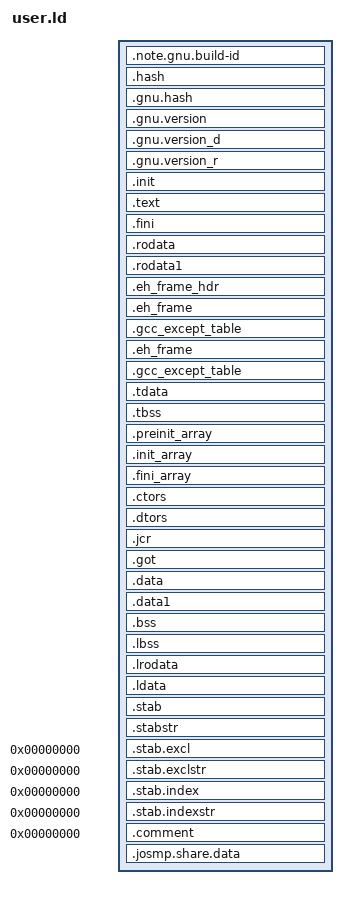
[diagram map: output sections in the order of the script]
/* Script for -z combreloc: combine and sort reloc sections */
OUTPUT_FORMAT("elf64-x86-64", "elf64-x86-64",
	      "elf64-x86-64")
OUTPUT_ARCH(i386:x86-64)
ENTRY(_start)

PHDRS
{
  text PT_LOAD FILEHDR PHDRS ;
  data PT_LOAD ;
  stab PT_LOAD ;
  josmp PT_LOAD ;
}

SECTIONS
{
  /* Read-only sections, merged into text segment: */
  PROVIDE (__executable_start = 0x400000); . = 0x400000 + SIZEOF_HEADERS;
  .note.gnu.build-id : { *(.note.gnu.build-id) }
  .hash           : { *(.hash) }
  .gnu.hash       : { *(.gnu.hash) }
  .gnu.version    : { *(.gnu.version) }
  .gnu.version_d  : { *(.gnu.version_d) }
  .gnu.version_r  : { *(.gnu.version_r) }
  .init           :
  {
    KEEP (*(.init))
  } : text =0x90909090
  .text           :
  {
    *(.text .stub .text.* .gnu.linkonce.t.*)
    KEEP (*(.text.*personality*))
    /* .gnu.warning sections are handled specially by elf32.em.  */
    *(.gnu.warning)
  } =0x90909090
  .fini           :
  {
    KEEP (*(.fini))
  } =0x90909090
  PROVIDE (__etext = .);
  PROVIDE (_etext = .);
  PROVIDE (etext = .);
  .rodata         : { *(.rodata .rodata.* .gnu.linkonce.r.*) }
  .rodata1        : { *(.rodata1) }
  .eh_frame_hdr : { *(.eh_frame_hdr) }
  .eh_frame       : ONLY_IF_RO { KEEP (*(.eh_frame)) }
  .gcc_except_table   : ONLY_IF_RO { *(.gcc_except_table .gcc_except_table.*) }
  /* Adjust the address for the data segment.  We want to adjust up to
     the same address within the page on the next page up.  */
  . = ALIGN (CONSTANT (MAXPAGESIZE)) - ((CONSTANT (MAXPAGESIZE) - .) & (CONSTANT (MAXPAGESIZE) - 1)); . = DATA_SEGMENT_ALIGN (CONSTANT (MAXPAGESIZE), CONSTANT (COMMONPAGESIZE));
  /* Exception handling  */
  .eh_frame       : ONLY_IF_RW { KEEP (*(.eh_frame)) }
  .gcc_except_table   : ONLY_IF_RW { *(.gcc_except_table .gcc_except_table.*) }
  /* Thread Local Storage sections  */
  .tdata	  : { *(.tdata .tdata.* .gnu.linkonce.td.*) }
  .tbss		  : { *(.tbss .tbss.* .gnu.linkonce.tb.*) *(.tcommon) }
  .preinit_array     :
  {
    PROVIDE_HIDDEN (__preinit_array_start = .);
    KEEP (*(.preinit_array))
    PROVIDE_HIDDEN (__preinit_array_end = .);
  }
  .init_array     :
  {
     PROVIDE_HIDDEN (__init_array_start = .);
     KEEP (*(SORT(.init_array.*)))
     KEEP (*(.init_array))
     PROVIDE_HIDDEN (__init_array_end = .);
  }
  .fini_array     :
  {
    PROVIDE_HIDDEN (__fini_array_start = .);
    KEEP (*(.fini_array))
    KEEP (*(SORT(.fini_array.*)))
    PROVIDE_HIDDEN (__fini_array_end = .);
  }
  .ctors          :
  {
    /* gcc uses crtbegin.o to find the start of
       the constructors, so we make sure it is
       first.  Because this is a wildcard, it
       doesn't matter if the user does not
       actually link against crtbegin.o; the
       linker won't look for a file to match a
       wildcard.  The wildcard also means that it
       doesn't matter which directory crtbegin.o
       is in.  */
    KEEP (*crtbegin.o(.ctors))
    KEEP (*crtbegin?.o(.ctors))
    /* We don't want to include the .ctor section from
       the crtend.o file until after the sorted ctors.
       The .ctor section from the crtend file contains the
       end of ctors marker and it must be last */
    KEEP (*(EXCLUDE_FILE (*crtend.o *crtend?.o ) .ctors))
    KEEP (*(SORT(.ctors.*)))
    KEEP (*(.ctors))
  } : data
  .dtors          :
  {
    KEEP (*crtbegin.o(.dtors))
    KEEP (*crtbegin?.o(.dtors))
    KEEP (*(EXCLUDE_FILE (*crtend.o *crtend?.o ) .dtors))
    KEEP (*(SORT(.dtors.*)))
    KEEP (*(.dtors))
  }
  .jcr            : { KEEP (*(.jcr)) }
  .got            : { *(.got) }
  . = DATA_SEGMENT_RELRO_END (24, .);
  .data           :
  {
    *(.data .data.* .gnu.linkonce.d.*)
    KEEP (*(.gnu.linkonce.d.*personality*))
    SORT(CONSTRUCTORS)
  }
  .data1          : { *(.data1) }
  _edata = .; PROVIDE (edata = .);
  __bss_start = .;
  .bss            :
  {
   *(.dynbss)
   *(.bss .bss.* .gnu.linkonce.b.*)
   *(COMMON)
   /* Align here to ensure that the .bss section occupies space up to
      _end.  Align after .bss to ensure correct alignment even if the
      .bss section disappears because there are no input sections.
      FIXME: Why do we need it? When there is no .bss section, we don't
      pad the .data section.  */
   . = ALIGN(. != 0 ? 64 / 8 : 1);
  }
  .lbss   :
  {
    *(.dynlbss)
    *(.lbss .lbss.* .gnu.linkonce.lb.*)
    *(LARGE_COMMON)
  }
  . = ALIGN(64 / 8);
  .lrodata   ALIGN(CONSTANT (MAXPAGESIZE)) + (. & (CONSTANT (MAXPAGESIZE) - 1)) :
  {
    *(.lrodata .lrodata.* .gnu.linkonce.lr.*)
  }
  .ldata   ALIGN(CONSTANT (MAXPAGESIZE)) + (. & (CONSTANT (MAXPAGESIZE) - 1)) :
  {
    *(.ldata .ldata.* .gnu.linkonce.l.*)
    . = ALIGN(. != 0 ? 64 / 8 : 1);
  }
  . = ALIGN(64 / 8);
  _end = .; PROVIDE (end = .);
  . = DATA_SEGMENT_END (.);
  /* Stabs debugging sections.  */
  /* provide debug stabs*/
  .stab		  : { 
			PROVIDE(__STAB_BEGIN__ = .);
			*(.stab);
			PROVIDE(__STAB_END__ = .);
	                BYTE(0)
			} : stab
  .stabstr	  : { 
			PROVIDE(__STABSTR_BEGIN__ = .);
			*(.stabstr);
			PROVIDE(__STABSTR_END__ = .);
	                BYTE(0)
			}
  .stab.excl     0 : { *(.stab.excl) }
  .stab.exclstr  0 : { *(.stab.exclstr) }
  .stab.index    0 : { *(.stab.index) }
  .stab.indexstr 0 : { *(.stab.indexstr) }
  .comment       0 : { *(.comment) }

  /* make josmp.share.data aligned and sit in a separate segment*/
  . = ALIGN(CONSTANT (MAXPAGESIZE));
  .josmp.share.data : {	*(.josmp.share.data); } : josmp

  /DISCARD/ : { *(.note.GNU-stack) *(.gnu_debuglink) }
}
